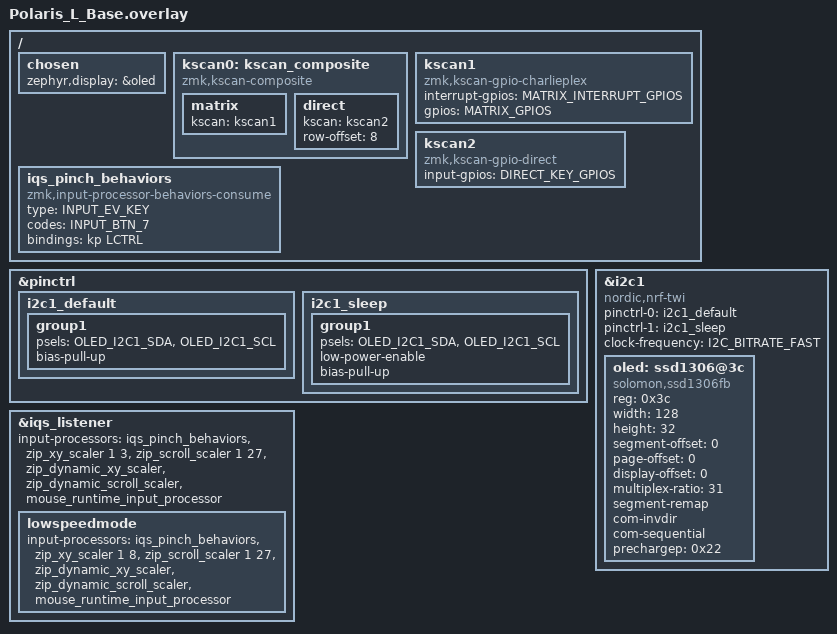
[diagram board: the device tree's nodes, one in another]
#include "Polaris.dtsi"
#include "Polaris_L_interior.dtsi"
#include <input/processors/runtime-input-processor.dtsi>

/ {
    chosen {
        zephyr,display = &oled;
    };

    kscan0: kscan_composite {
        compatible = "zmk,kscan-composite";
        matrix {
            kscan = <&kscan1>;
        };
        direct {
            kscan = <&kscan2>;
            row-offset = <8>;
        };
    };

    kscan1: kscan1 {
        compatible = "zmk,kscan-gpio-charlieplex";
        interrupt-gpios = MATRIX_INTERRUPT_GPIOS;
        gpios
            = MATRIX_GPIOS
            ;
    };
    
    kscan2: kscan2 {
        compatible = "zmk,kscan-gpio-direct";
        input-gpios
            = DIRECT_KEY_GPIOS
            ;
    };
};

&pinctrl {    
    i2c1_default: i2c1_default {
        group1 {
            psels = <OLED_I2C1_SDA>,
                    <OLED_I2C1_SCL>;
            bias-pull-up;
        };
    };
      
    i2c1_sleep: i2c1_sleep {
        group1 {
            psels = <OLED_I2C1_SDA>,
                    <OLED_I2C1_SCL>;
            low-power-enable;
            bias-pull-up;
        };
    };
};

&i2c1 {
    status = "okay";
    compatible = "nordic,nrf-twi";
    pinctrl-0 = <&i2c1_default>;
    pinctrl-1 = <&i2c1_sleep>;
    pinctrl-names = "default", "sleep";
    clock-frequency = <I2C_BITRATE_FAST>; 
    
    oled: ssd1306@3c {
        compatible = "solomon,ssd1306fb";
        reg = <0x3c>;
        width = <128>;
        height = <32>;
        segment-offset = <0>;
        page-offset = <0>;
        display-offset = <0>;
        multiplex-ratio = <31>;
        segment-remap;
        com-invdir;
        com-sequential;

        prechargep = <0x22>;
    };
};

/ {
    iqs_pinch_behaviors: iqs_pinch_behaviors {
        compatible = "zmk,input-processor-behaviors-consume";
        #input-processor-cells = <0>;
        type = <INPUT_EV_KEY>;
        codes = <INPUT_BTN_7>;
        bindings = <&kp LCTRL>;
    };
};

&iqs_listener {
    input-processors = <&iqs_pinch_behaviors>,
                       <&zip_xy_scaler 1 3>,
                       <&zip_scroll_scaler 1 27>,
                       <&zip_dynamic_xy_scaler>,
                       <&zip_dynamic_scroll_scaler>,
                       <&mouse_runtime_input_processor>;

    lowspeedmode {
        input-processors = <&iqs_pinch_behaviors>,
                           <&zip_xy_scaler 1 8>,
                           <&zip_scroll_scaler 1 27>,
                           <&zip_dynamic_xy_scaler>,
                           <&zip_dynamic_scroll_scaler>,
                           <&mouse_runtime_input_processor>;
    };
};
